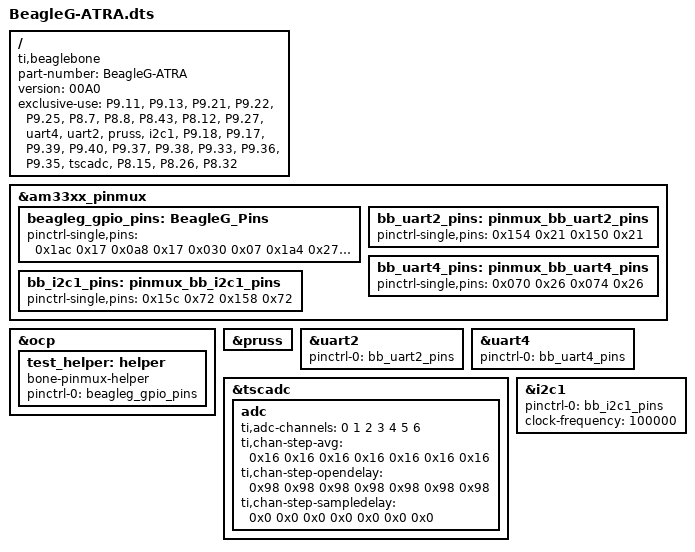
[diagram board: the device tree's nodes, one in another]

/dts-v1/;
/plugin/;

/{
  compatible = "ti,beaglebone", "ti,beaglebone-black", "ti,beaglebone-green";
  part-number = "BeagleG-ATRA";  /* BeagleG/Bumps 'cape' */
  version = "00A0";

  exclusive-use = /* the pin header uses */
                  /* UARTS */
                  "P9.11",        /* uart4_rxd */
                  "P9.13",        /* uart4_txd */
                  "P9.21",        /* uart2_txd */
                  "P9.22",        /* uart2_rxd */

                  /* GPIOs */
                  "P9.25",        /* MOTORS ENABLE GPO0 */

                  /* Valves */
                  "P8.7",        /* STEP GPO9 OUT*/
                  "P8.8",        /* DIR GPO10 OUT*/

                  /* A component */
                  "P8.43",        /* STEP GPO1 OUT*/
                  "P8.12",        /* DIR GPO2 OUT*/

                  /* End Switch */
                  "P9.27",

                  /* the peripherals used */
                  "uart4",       // TMCL uart
                  "uart2",
                  "pruss",       // Programmable realtime unit
                  "i2c1",
                  "P9.18",		// i2c1_sda
              		"P9.17",		// i2c1_scl

                  /* Analogs in */
                  "P9.39",      // AIN0
                  "P9.40",      // AIN1
                  "P9.37",      // AIN2
                  "P9.38",      // AIN3
                  "P9.33",      // AIN4
                  "P9.36",      // AIN5
                  "P9.35",      // AIN6
                  "tscadc",     // hardware ip used

                  /* Buttons input */
                  "P8.15",      // Start

                  /* termreg PWM outpus */
                  "P8.26",     // PWM0
                  "P8.32";     // PWM1

  fragment@0 {
    target = <&am33xx_pinmux>;
    __overlay__ {
      beagleg_gpio_pins: BeagleG_Pins {
        pinctrl-single,pins = <
          /* Motor enable */
          0x1ac 0x17 /* P9_25, pullup */

          /* Motor step pins */
          0x0a8 0x17  /* STEPX P8.43 */

          /* Motor dir pins */
          0x030 0x07  /* DIRX P8.12 */

          /* End Switch */
          0x1a4 0x27  /* P9_27, endswitch */

          /* Valves */
          0x090 0x07  /* STEPB P8.7 */
          0x094 0x07  /* DIRB  P8.8 */

          /* termreg PWM outpus */
          0x07c 0x07  /* PWM0  P8.26 */
          0x0dc 0x07  /* PWM1  P8.32 */

          /* Inputs */
          0x03c 0x37  /* Start input button */
        >;
      };

      /* UARTS */
      bb_uart2_pins: pinmux_bb_uart2_pins {
        pinctrl-single,pins = <
          0x154 0x21 /* UART2 TX */
          0x150 0x21 /* UART2 RX */
        >;
      };

      bb_uart4_pins: pinmux_bb_uart4_pins {
        pinctrl-single,pins = <
          0x070 0x26 /* UART4 RX */
          0x074 0x26 /* UART4 TX */
        >;
      };

      bb_i2c1_pins: pinmux_bb_i2c1_pins {
        pinctrl-single,pins = <
          0x15c 0x72
          0x158 0x72
        >;
      };
    };
  };

  fragment@1 {
    target = <&ocp>;
    __overlay__ {
      test_helper: helper {
        compatible = "bone-pinmux-helper";
        pinctrl-names = "default";
        pinctrl-0 = <&beagleg_gpio_pins>;
        status = "okay";
      };
    };
  };

  fragment@2 {
    target = <&pruss>;
    __overlay__ {
      status = "okay";
    };
  };

  fragment@3 {
    target = <&uart2>;
    __overlay__ {
      status = "okay";
      pinctrl-names = "default";
      pinctrl-0 = <&bb_uart2_pins>;
    };
  };

  fragment@4 {
    target = <&uart4>;
    __overlay__ {
      status = "okay";
      pinctrl-names = "default";
      pinctrl-0 = <&bb_uart4_pins>;
    };
  };

  fragment@5 {
    target = <&tscadc>;
    __overlay__ {
      status = "okay";
      adc {
        ti,adc-channels = <0 1 2 3 4 5 6>;
        ti,chan-step-avg = <0x16 0x16 0x16 0x16 0x16 0x16 0x16>;
        ti,chan-step-opendelay = <0x98 0x98 0x98 0x98 0x98 0x98 0x98>;
        ti,chan-step-sampledelay = <0x0 0x0 0x0 0x0 0x0 0x0 0x0>;
      };
    };
  };

  fragment@6 {
    target = <&i2c1>; // i2c1 is numbered correctly
    __overlay__ {
      status = "okay";
      pinctrl-names = "default";
      pinctrl-0 = <&bb_i2c1_pins>;

      // configuration start
      clock-frequency = <100000>;

      #address-cells = <1>;
      #size-cells = <0>;

      // add any i2c devices on the bus here

      // commented out example of a touchscreen (taken from BB-BONE-LCD7-01-00A4)
      /*
      maxtouch@4a {
        compatible = "mXT224";
        reg = <0x4a>;
        interrupt-parent = <&gpio4>;
        interrupts = <19 0x0>;
        atmel,irq-gpio = <&gpio4 19 0>;
      };
      */
    };
  };
};
